# MKL28T7_CORE0 register map
Vendor: Freescale Semiconductor, Inc.; Series: Kinetis_L; File version: 1.6
CPU: CM0PLUS r0p0, little endian, no MPU, no FPU, VTOR, 2 interrupt priority bits
Registers are 32-bit, read-write, reset 0x0 unless marked. A register's access mark holds for its fields unless they carry their own. Offsets are from the block's base; [hi:lo] are bit positions; {n}, {i} and the like mark numbered series; 'fields as' and 'values as' point back to an identical list.

## EMVSIM0 — EMVSIM
Base 0x4004E000; register names take the prefix EMVSIM0_
0x00 VER_ID ro — Version ID Register
  [31:0] VER — Version ID of the module
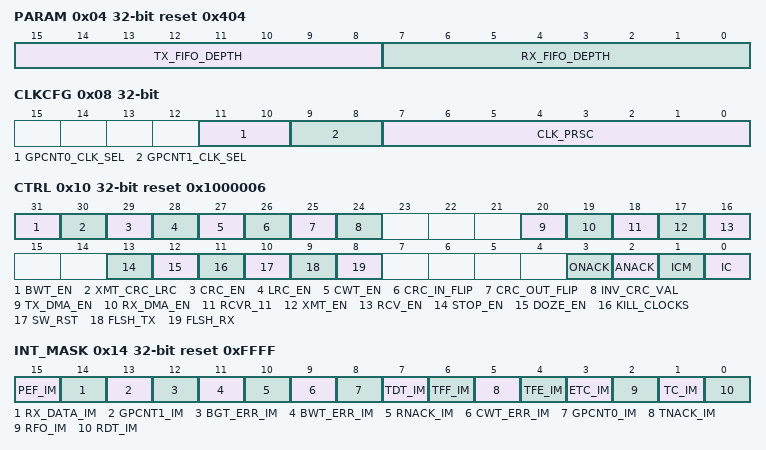
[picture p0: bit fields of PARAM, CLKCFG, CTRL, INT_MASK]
0x04 PARAM ro reset 0x404 — Parameter Register
  [15:8] TX_FIFO_DEPTH — Transmit FIFO Depth
  [7:0] RX_FIFO_DEPTH — Receive FIFO Depth
0x08 CLKCFG — Clock Configuration Register
  [11:10] GPCNT0_CLK_SEL — General Purpose Counter 0 Clock Select
    0=Disabled / Reset (default); 1=Card Clock; 2=Receive Clock; 3=ETU Clock (transmit clock)
  [9:8] GPCNT1_CLK_SEL — General Purpose Counter 1 Clock Select
    values as GPCNT0_CLK_SEL
  [7:0] CLK_PRSC — Clock Prescaler Value
    2=Divide by 2
0x0C DIVISOR reset 0x174 — Baud Rate Divisor Register
  [8:0] DIVISOR_VALUE — Divisor (F/D) Value
    0x174=Divisor value for F = 372 and D = 1 (default)
0x10 CTRL reset 0x1000006 — Control Register
  [31] BWT_EN — Block Wait Time Counter Enable
    0=Disable BWT, BGT Counters (default); 1=Enable BWT, BGT Counters
  [30] XMT_CRC_LRC — Transmit CRC or LRC Enable
    0=No CRC or LRC value is transmitted (default); 1=Transmit LRC or CRC info when FIFO empties (whichever is enabled)
  [29] CRC_EN — CRC Enable
    0=16-bit Cyclic Redundancy Checking disabled (default); 1=16-bit Cyclic Redundancy Checking enabled
  [28] LRC_EN — LRC Enable
    0=8-bit Linear Redundancy Checking disabled (default); 1=8-bit Linear Redundancy Checking enabled
  [27] CWT_EN — Character Wait Time Counter Enable
    0=Character Wait time Counter is disabled (default); 1=Character Wait time counter is enabled
  [26] CRC_IN_FLIP — CRC Input Byte's Bit Reversal or Flip Control
    0=Bits in the input byte will not be reversed (i.e. 7:0 will remain 7:0) before the CRC calculation (default); 1=Bits in the input byte will be reversed (i.e. 7:0 will become 0:7) before CRC calculation
  [25] CRC_OUT_FLIP — CRC Output Value Bit Reversal or Flip
    0=Bits within the CRC output bytes will not be reversed i.e. 15:0 will remain 15:0 (default); 1=Bits within the CRC output bytes will be reversed i.e. 15:0 will become {8:15,0:7}
  [24] INV_CRC_VAL — Invert bits in the CRC Output Value
    0=Bits in CRC Output value will not be inverted; 1=Bits in CRC Output value will be inverted. (default)
  [20] TX_DMA_EN — Transmit DMA Enable
    0=No DMA Write Request asserted for Transmitter (default); 1=DMA Write Request asserted for Transmitter
  [19] RX_DMA_EN — Receive DMA Enable
    0=No DMA Read Request asserted for Receiver (default); 1=DMA Read Request asserted for Receiver
  [18] RCVR_11 — Receiver 11 ETU Mode Enable
    0=Receiver configured for 12 ETU operation mode (default); 1=Receiver configured for 11 ETU operation mode
  [17] XMT_EN — Transmitter Enable
    0=EMV SIM Transmitter disabled (default); 1=EMV SIM Transmitter enabled
  [16] RCV_EN — Receiver Enable
    0=EMV SIM Receiver disabled (default); 1=EMV SIM Receiver enabled
  [13] STOP_EN — STOP Enable
    0=STOP instruction shuts down all EMV SIM clocks (default); 1=STOP instruction shuts down all clocks except for the Smart Card Clock (SCK) (clock provided to Smart Card)
  [12] DOZE_EN — Doze Enable
    0=DOZE instruction will gate all internal EMV SIM clocks as well as the Smart Card clock when the transmit FIFO is empty (default); 1=DOZE instruction has no effect on EMV SIM module
  [11] KILL_CLOCKS — Kill all internal clocks
    0=EMV SIM input clock enabled (default); 1=EMV SIM input clock is disabled
  [10] SW_RST wo — Software Reset Bit
    0=EMV SIM Normal operation (default); 1=EMV SIM held in Reset
  [9] FLSH_TX wo — Flush Transmitter Bit
    0=EMV SIM Transmitter normal operation (default); 1=EMV SIM Transmitter held in Reset
  [8] FLSH_RX wo — Flush Receiver Bit
    0=EMV SIM Receiver normal operation (default); 1=EMV SIM Receiver held in Reset
  [3] ONACK — Overrun NACK Enable
    0=NACK generation on overrun is disabled (default); 1=NACK generation on overrun is enabled
  [2] ANACK — Auto NACK Enable
    0=NACK generation on errors disabled; 1=NACK generation on errors enabled (default)
  [1] ICM — Initial Character Mode
    0=Initial Character Mode disabled; 1=Initial Character Mode enabled (default)
  [0] IC — Inverse Convention
    0=Direction convention transfers enabled (default); 1=Inverse convention transfers enabled
0x14 INT_MASK reset 0xFFFF — Interrupt Mask Register
  [15] PEF_IM — Parity Error Interrupt Mask
    0=PEF interrupt enabled; 1=PEF interrupt masked (default)
  [14] RX_DATA_IM — Receive Data Interrupt Mask
    0=RX_DATA interrupt enabled; 1=RX_DATA interrupt masked (default)
  [13] GPCNT1_IM — General Purpose Counter 1 Timeout Interrupt Mask
    0=GPCNT1_TO interrupt enabled; 1=GPCNT1_TO interrupt masked (default)
  [12] BGT_ERR_IM — Block Guard Time Error Interrupt
    0=BGT_ERR interrupt enabled; 1=BGT_ERR interrupt masked (default)
  [11] BWT_ERR_IM — Block Wait Time Error Interrupt Mask
    0=BWT_ERR interrupt enabled; 1=BWT_ERR interrupt masked (default)
  [10] RNACK_IM — Receiver NACK Threshold Interrupt Mask
    0=RTE interrupt enabled; 1=RTE interrupt masked (default)
  [9] CWT_ERR_IM — Character Wait Time Error Interrupt Mask
    0=CWT_ERR interrupt enabled; 1=CWT_ERR interrupt masked (default)
  [8] GPCNT0_IM — General Purpose Timer 0 Timeout Interrupt Mask
    0=GPCNT0_TO interrupt enabled; 1=GPCNT0_TO interrupt masked (default)
  [7] TDT_IM — Transmit Data Threshold Interrupt Mask
    0=TDTF interrupt enabled; 1=TDTF interrupt masked (default)
  [6] TFF_IM — Transmit FIFO Full Interrupt Mask
    0=TFF interrupt enabled; 1=TFF interrupt masked (default)
  [5] TNACK_IM — Transmit NACK Threshold Interrupt Mask
    0=TNTE interrupt enabled; 1=TNTE interrupt masked (default)
  [4] TFE_IM — Transmit FIFO Empty Interrupt Mask
    0=TFE interrupt enabled; 1=TFE interrupt masked (default)
  [3] ETC_IM — Early Transmit Complete Interrupt Mask
    0=ETC interrupt enabled; 1=ETC interrupt masked (default)
  [2] RFO_IM — Receive FIFO Overflow Interrupt Mask
    0=RFO interrupt enabled; 1=RFO interrupt masked (default)
  [1] TC_IM — Transmit Complete Interrupt Mask
    0=TCF interrupt enabled; 1=TCF interrupt masked (default)
  [0] RDT_IM — Receive Data Threshold Interrupt Mask
    0=RDTF interrupt enabled; 1=RDTF interrupt masked (default)
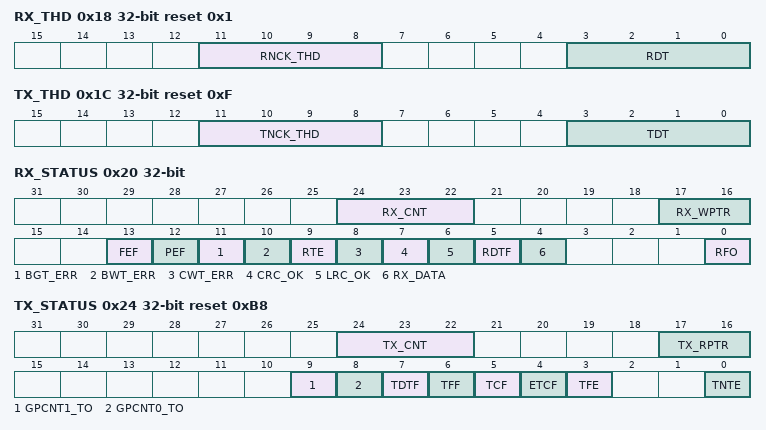
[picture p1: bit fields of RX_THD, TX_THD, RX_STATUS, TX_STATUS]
0x18 RX_THD reset 0x1 — Receiver Threshold Register
  [11:8] RNCK_THD — Receiver NACK Threshold Value
    0=Zero Threshold. RTE will not be set
  [3:0] RDT — Receiver Data Threshold Value
0x1C TX_THD reset 0xF — Transmitter Threshold Register
  [11:8] TNCK_THD — Transmitter NACK Threshold Value
    0=TNTE will never be set; retransmission after NACK reception is disabled; 1=TNTE will be set after 1 nack is received; 0 retransmissions occurs; 2=TNTE will be set after 2 nacks are received; at most 1 retransmission occurs; 3=TNTE will be set after 3 nacks are received; at most 2 retransmissions occurs; 15=TNTE will be set after 15 nacks are received; at most 14 retransmissions occurs
  [3:0] TDT — Transmitter Data Threshold Value
0x20 RX_STATUS — Receive Status Register
  [24:22] RX_CNT ro — Receive FIFO Byte Count
    0=FIFO is emtpy
  [17:16] RX_WPTR ro — Receive FIFO Write Pointer Value
  [13] FEF — Frame Error Flag
    0=No frame error detected; 1=Frame error detected
  [12] PEF — Parity Error Flag
    0=No parity error detected; 1=Parity error detected
  [11] BGT_ERR — Block Guard Time Error Flag
    0=Block guard time was sufficient; 1=Block guard time was too small
  [10] BWT_ERR — Block Wait Time Error Flag
    0=Block wait time not exceeded; 1=Block wait time was exceeded
  [9] RTE — Received NACK Threshold Error Flag
    0=Number of NACKs generated by the receiver is less than the value programmed in RTH[3:0]; 1=Number of NACKs generated by the receiver is equal to the value programmed in RTH[3:0]
  [8] CWT_ERR — Character Wait Time Error Flag
    0=No CWT violation has occurred (default); 1=Time between two consecutive characters has exceeded the value in CHAR_WAIT
  [7] CRC_OK ro — CRC Check OK Flag
    0=Current CRC value does not match remainder; 1=Current calculated CRC value matches the expected result
  [6] LRC_OK ro — LRC Check OK Flag
    0=Current LRC value does not match remainder; 1=Current calculated LRC value matches the expected result (i.e. zero).
  [5] RDTF ro — Receive Data Threshold Interrupt Flag
    0=Number of unread bytes in receive FIFO less than the value set by RDT[3:0] (default); 1=Number of unread bytes in receive FIFO greater or than equal to value set by RDT[3:0]
  [4] RX_DATA — Receive Data Interrupt Flag
    0=No new byte is received; 1=New byte is received ans stored in Receive FIFO
  [0] RFO — Receive FIFO Overflow Flag
    0=No overrun error has occurred (default); 1=A byte was received when the received FIFO was already full
0x24 TX_STATUS reset 0xB8 — Transmitter Status Register
  [24:22] TX_CNT ro — Transmit FIFO Byte Count
    0=FIFO is emtpy
  [17:16] TX_RPTR ro — Transmit FIFO Read Pointer
  [9] GPCNT1_TO — General Purpose Counter 1 Timeout Flag
    0=GPCNT1_VAL time not reached, or bit has been cleared. (default); 1=General Purpose counter has reached the GPCNT1_VAL value
  [8] GPCNT0_TO — General Purpose Counter 0 Timeout Flag
    0=GPCNT0_VAL time not reached, or bit has been cleared. (default); 1=General Purpose counter has reached the GPCNT0_VAL value
  [7] TDTF ro — Transmit Data Threshold Flag
    0=Number of bytes in FIFO is greater than TDT[3:0], or bit has been cleared; 1=Number of bytes in FIFO is less than or equal to TDT[3:0] (default)
  [6] TFF — Transmit FIFO Full Flag
    0=Transmit FIFO Full condition has not occurred (default); 1=A Transmit FIFO Full condition has occurred
  [5] TCF — Transmit Complete Flag
    0=Transmit pending or in progress; 1=Transmit complete (default)
  [4] ETCF — Early Transmit Complete Flag
    values as TCF
  [3] TFE — Transmit FIFO Empty Flag
    0=Transmit FIFO is not empty; 1=Transmit FIFO is empty (default)
  [0] TNTE — Transmit NACK Threshold Error Flag
    0=Transmit NACK threshold has not been reached (default); 1=Transmit NACK threshold reached; transmitter frozen
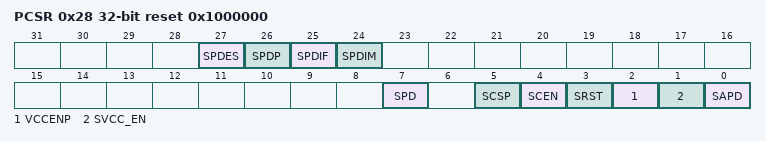
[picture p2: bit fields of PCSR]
0x28 PCSR reset 0x1000000 — Port Control and Status Register
  [27] SPDES — SIM Presence Detect Edge Select
    0=Falling edge on the pin (default); 1=Rising edge on the pin
  [26] SPDP ro — Smart Card Presence Detect Pin Status
    0=SIM Presence Detect pin is logic low; 1=SIM Presence Detectpin is logic high
  [25] SPDIF — Smart Card Presence Detect Interrupt Flag
    0=No insertion or removal of Smart Card detected on Port (default); 1=Insertion or removal of Smart Card detected on Port
  [24] SPDIM — Smart Card Presence Detect Interrupt Mask
    0=SIM presence detect interrupt is enabled; 1=SIM presence detect interrupt is masked (default)
  [7] SPD — Auto Power Down Control
    0=No effect (default); 1=Start Auto Powerdown or Power Down is in progress
  [5] SCSP — Smart Card Clock Stop Polarity
    0=Clock is logic 0 when stopped by SCEN; 1=Clock is logic 1 when stopped by SCEN
  [4] SCEN — Clock Enable for Smart Card
    0=Smart Card Clock Disabled; 1=Smart Card Clock Enabled
  [3] SRST — Reset to Smart Card
    0=Smart Card Reset is asserted (default); 1=Smart Card Reset is de-asserted
  [2] VCCENP — VCC Enable Polarity Control
    0=VCC_EN is active high. Polarity of SVCC_EN is unchanged.; 1=VCC_EN is active low. Polarity of SVCC_EN is inverted.
  [1] SVCC_EN — Vcc Enable for Smart Card
    0=Smart Card Voltage disabled (default); 1=Smart Card Voltage enabled
  [0] SAPD — Auto Power Down Enable
    0=Auto power down disabled (default); 1=Auto power down enabled
0x2C RX_BUF ro — Receive Data Read Buffer
  [7:0] RX_BYTE — Receive Data Byte Read
0x30 TX_BUF — Transmit Data Buffer
  [7:0] TX_BYTE wo — Transmit Data Byte
0x34 TX_GETU — Transmitter Guard ETU Value Register
  [7:0] GETU — Transmitter Guard Time Value in ETU
    0=no additional ETUs inserted (default); 1=1 additional ETU inserted; 254=254 additional ETUs inserted; 255=Subtracts one ETU by reducing the number of STOP bits from two to one
0x38 CWT_VAL reset 0xFFFF — Character Wait Time Value Register
  [15:0] CWT — Character Wait Time Value
0x3C BWT_VAL reset 0xFFFFFFFF — Block Wait Time Value Register
  [31:0] BWT — Block Wait Time Value
0x40 BGT_VAL — Block Guard Time Value Register
  [15:0] BGT — Block Guard Time Value
0x44 GPCNT0_VAL reset 0xFFFF — General Purpose Counter 0 Timeout Value Register
  [15:0] GPCNT0 — General Purpose Counter 0 Timeout Value
0x48 GPCNT1_VAL reset 0xFFFF — General Purpose Counter 1 Timeout Value
  [15:0] GPCNT1
